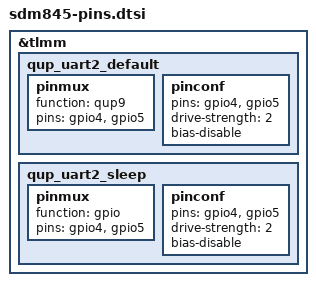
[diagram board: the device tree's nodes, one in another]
// SPDX-License-Identifier: GPL-2.0
/*
 * Copyright (c) 2018, The Linux Foundation. All rights reserved.
 */

&tlmm {
	qup_uart2_default: qup_uart2_default {
		pinmux {
			function = "qup9";
			pins = "gpio4", "gpio5";
		};

		pinconf {
			pins = "gpio4", "gpio5";
			drive-strength = <2>;
			bias-disable;
		};
	};

	qup_uart2_sleep: qup_uart2_sleep {
		pinmux {
			function = "gpio";
			pins = "gpio4", "gpio5";
		};

		pinconf {
			pins = "gpio4", "gpio5";
			drive-strength = <2>;
			bias-disable;
		};
	};
};
